# vcp_data register map
Vendor: Texas Instruments
Peripheral module from a debugger description file (folder Keystone2).
Registers are 32-bit, read-write, no defined reset value unless marked. A register's access mark holds for its fields unless they carry their own. Offsets are as the file gives them; lines under a group give offsets from that group; [hi:lo] are bit positions; {n}, {i} and the like mark numbered series; 'fields as' and 'values as' point back to an identical list; <NAME> marks a mode.

## VCP2_7_DATA
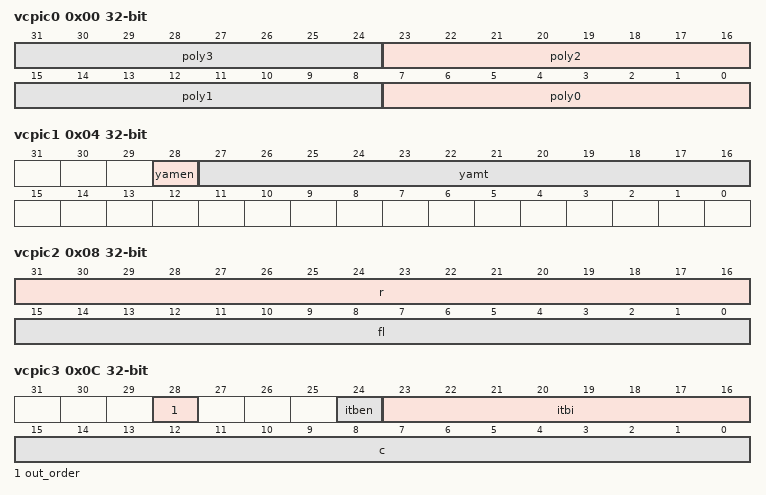
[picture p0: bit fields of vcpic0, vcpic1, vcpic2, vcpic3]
0x00 vcpic0
  [8n+7:8n] poly{n} (n=0..3)
0x04 vcpic1
  [28] yamen, [27:16] yamt
0x08 vcpic2
  [31:16] r, [15:0] fl
0x0C vcpic3
  [28] out_order, [24] itben, [23:16] itbi, [15:0] c
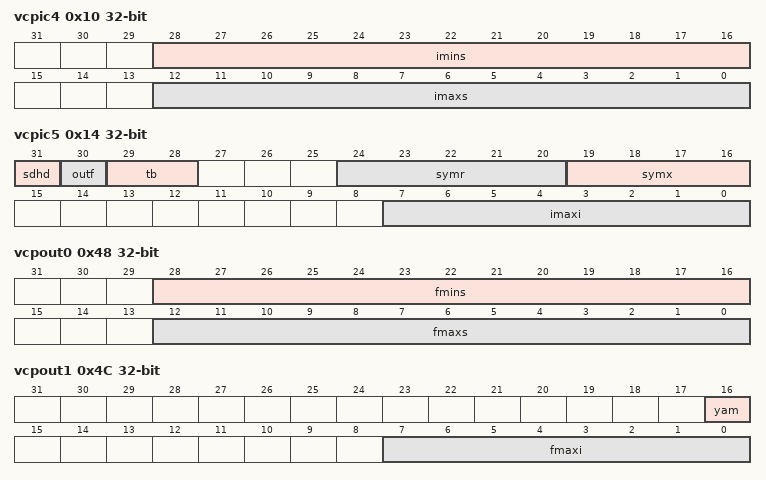
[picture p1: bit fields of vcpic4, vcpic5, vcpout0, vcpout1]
0x10 vcpic4
  [28:16] imins, [12:0] imaxs
0x14 vcpic5
  [31] sdhd, [30] outf, [29:28] tb, [24:20] symr, [19:16] symx, [7:0] imaxi
0x48 vcpout0
  [28:16] fmins, [12:0] fmaxs
0x4C vcpout1
  [16] yam, [7:0] fmaxi
0x80 vcpwbm
  [31:0] write
0xC0 vcprdecs
  [31:0] read
